# HK32L0xx register map
Vendor: HKMicroChip Ltd.; Series: HK32L0xx; File version: 1.3
CPU: CM0 r0p0, little endian, no MPU, no FPU, 3 interrupt priority bits
Registers are 32-bit, read-write, reset 0x0 unless marked. A register's access mark holds for its fields unless they carry their own. Offsets are from the block's base; [hi:lo] are bit positions; {n}, {i} and the like mark numbered series.

## DAC
Base 0x40007400
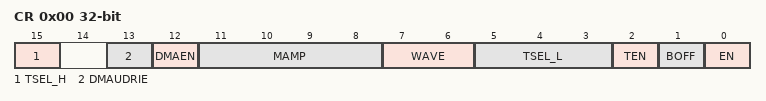
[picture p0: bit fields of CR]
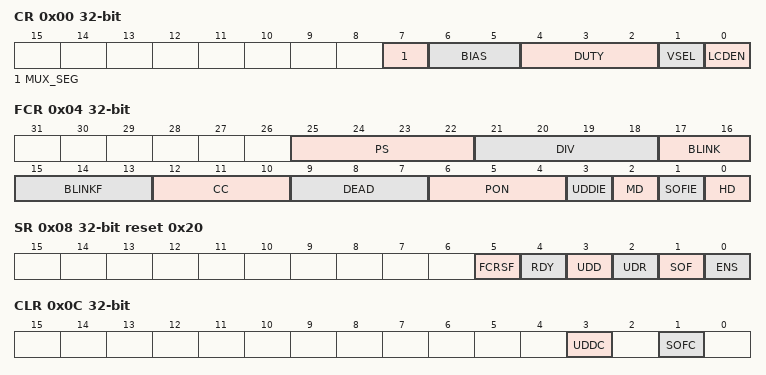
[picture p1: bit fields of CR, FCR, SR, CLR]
0x00 CR
  [15] TSEL_H — DAC trigger channel selection high bit
  [13] DMAUDRIE — DAC channel DMA underrun interrupt enable
  [12] DMAEN — DAC channel DMA enable
  [11:8] MAMP — DAC channel mask/amplitude selector
  [7:6] WAVE — DAC channel noise/triangle wave generation enable
  [5:3] TSEL_L — DAC trigger channel selection low bit
  [2] TEN — DAC channel trigger enable
  [1] BOFF — DAC channel output buffer disable
  [0] EN — DAC channel enable
0x04 SWTRIGR wo
  [0] SWTRIG — DAC channel software trigger
0x08 DHR12R
  [11:0] DACDHR12R — DAC channel 12-bit right-aligned data
0x0C DHR12L
  [15:4] DACDHR12L — DAC channel 12-bit right-aligned data
0x10 DHR8R
  [7:0] DACDHR8R — DAC channel 8-bit right-aligned data
0x2C DOR ro
  [11:0] DACDOR — DAC channel data output
0x34 SR
  [13] DMAUDR — DAC channel DMA underrun flag

## LCD
Base 0x40002400
0x00 CR
  [7] MUX_SEG — Mux segment enable
  [6:5] BIAS — Bias selector
  [4:2] DUTY — Duty selection
  [1] VSEL — Voltage source selection
  [0] LCDEN — LCD controller enable
0x04 FCR
  [25:22] PS — PS 16-bit prescaler
  [21:18] DIV — DIV clock divider
  [17:16] BLINK — Blink mode selection
  [15:13] BLINKF — Blink frequency selection
  [12:10] CC — Contrast control
  [9:7] DEAD — Dead time duration
  [6:4] PON — Pulse ON duration
  [3] UDDIE — Update display done interrupt enable
  [2] MD — Middle drive enable
  [1] SOFIE — Start of frame interrupt enable
  [0] HD — High drive enable
0x08 SR access per field reset 0x20
  [5] FCRSF ro — LCD Frame Control Register Synchronization flag
  [4] RDY ro — Ready flag
  [3] UDD ro — Update Display Done
  [2] UDR rw — Update display request
  [1] SOF ro — Start of frame flag
  [0] ENS ro — LCD enabled status
0x0C CLR wo
  [3] UDDC — Update display done clear
  [1] SOFC — Start of frame flag clear
{0x14+4i} RAM{i} (i=0..15)
  [31:0] SEGMENT_DATA — The Value write to RAM
0x80 COMENR
  [7:0] COMEN — COM Enable
0x84 SEGENR0
  [31:0] SEGEN — SEG Enable

## COMP1
Base 0x40010118
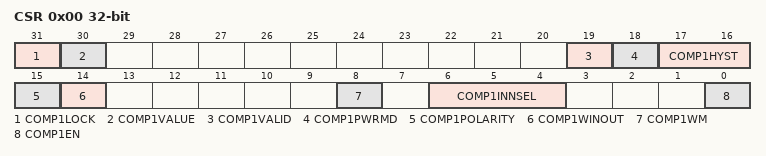
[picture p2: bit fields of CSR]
0x00 CSR access per field
  [31] COMP1LOCK rw — COMP1_CSR register lock bit
  [30] COMP1VALUE ro — Comparator 1 output status bit
  [19] COMP1VALID rw — Comparator 1 valid output selection
  [18] COMP1PWRMD rw — Comparator 1 power mode selection
  [17:16] COMP1HYST rw — Comparator 1 hysteresis
  [15] COMP1POLARITY rw — Comparator 1 polarity selection bit
  [14] COMP1WINOUT rw — Comparator 1 output selection
  [8] COMP1WM rw — Comparator 1 window mode selection bit
  [6:4] COMP1INNSEL rw — Comparator 1 inverting input selection
  [0] COMP1EN rw — Comparator 1 enable bit

## COMP2
Base 0x4001011C
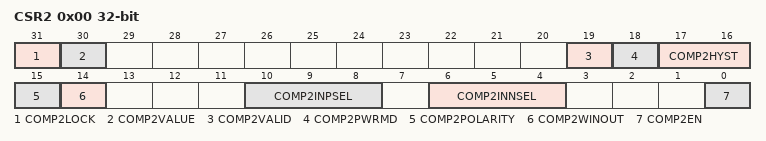
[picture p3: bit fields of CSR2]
0x00 CSR2 access per field
  [31] COMP2LOCK rw — COMP2_CSR register lock bit
  [30] COMP2VALUE ro — Comparator 2 output status bit
  [19] COMP2VALID rw — Comparator 2 valid output selection
  [18] COMP2PWRMD rw — Comparator 2 power mode selection
  [17:16] COMP2HYST rw — Comparator 2 hysteresis
  [15] COMP2POLARITY rw — Comparator 2 polarity selection bit
  [14] COMP2WINOUT rw — Comparator 2 output selection
  [10:8] COMP2INPSEL rw — Comparator 2 non inverting input selection
  [6:4] COMP2INNSEL rw — Comparator 2 inverting input selection
  [0] COMP2EN rw — Comparator 2 enable bit

## OPA1
Base 0x40010238
Same registers: OPA2 0x4001023C, OPA3 0x40010240
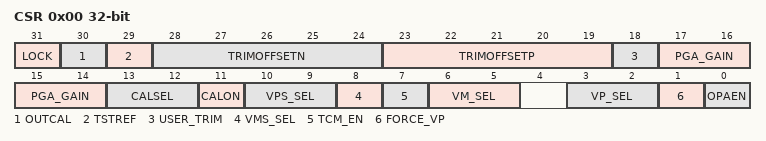
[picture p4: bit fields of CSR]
0x00 CSR access per field
  [31] LOCK rw — OPAx_CSR register lock bit
  [30] OUTCAL ro — OPAx output status flag
  [29] TSTREF rw — OPA1 output to ADC enable
  [28:24] TRIMOFFSETN rw — NMOS
  [23:19] TRIMOFFSETP rw — PMOS
  [18] USER_TRIM rw — User trimming enable
  [17:14] PGA_GAIN rw — Gain in PGA mode configuration
  [13:12] CALSEL rw — Calibration selection
  [11] CALON rw — Calibration mode enable
  [10:9] VPS_SEL rw — OPAx Second Non inverting input selection
  [8] VMS_SEL rw — OPAx Second inverting input selection
  [7] TCM_EN rw — OPAx Default and Second Enable
  [6:5] VM_SEL rw — OPAx inverting input selection
  [3:2] VP_SEL rw — OPAx Non inverting input selection
  [1] FORCE_VP rw — Forces calibration
  [0] OPAEN rw — OPAx enable

## BEEPER
Base 0x40012000
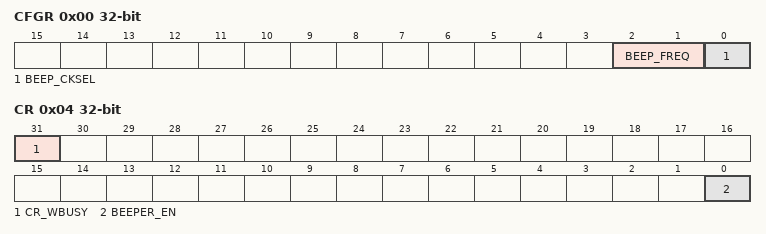
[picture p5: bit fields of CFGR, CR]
0x00 CFGR
  [2:1] BEEP_FREQ — Beep clock source divider
  [0] BEEP_CKSEL — Beep elapsed time clock select
0x04 CR access per field
  [31] CR_WBUSY ro — CR write busy
  [0] BEEPER_EN rw — Beeper enable

## AES
Base 0x40026000
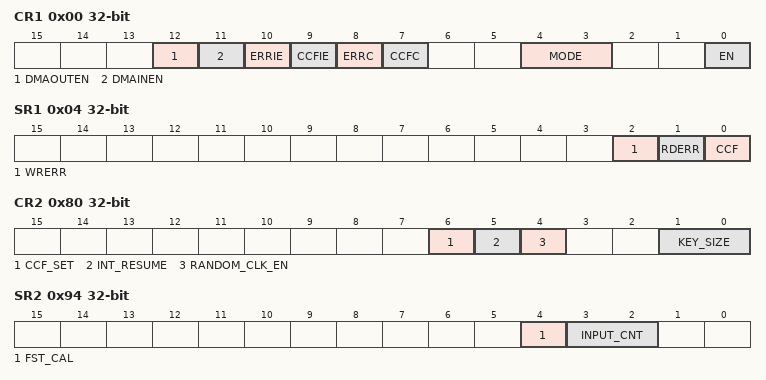
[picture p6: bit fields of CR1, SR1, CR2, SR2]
0x00 CR1
  [12] DMAOUTEN — Enable DMA management of data output phase
  [11] DMAINEN — Enable DMA management of data input phase
  [10] ERRIE — Error interrupt enable
  [9] CCFIE — CCF flag interrupt enable
  [8] ERRC — Error clear
  [7] CCFC — Computation complete flag clear
  [4:3] MODE — AES operating mode selection
  [0] EN — AES enable
0x04 SR1 ro
  [2] WRERR — Write error flag
  [1] RDERR — Read error flag
  [0] CCF — Computation complete flag
0x08 DINR
  [31:0] DINR — Data input register
0x0C DOUTR
  [31:0] DOUTR — Data output register
0x10 KEYR0
  [31:0] KEYR0 — LSB of AES key register
{0x10+4i} KEYR{i} (i=1..3)
  [31:0] KEYR{i} — AES key register
0x80 CR2
  [6] CCF_SET — Force to set bit AES_SR.CCF
  [5] INT_RESUME — Indicate the AES to resume from the interrupt service program
  [4] RANDOM_CLK_EN — Random number of TRNG output to randomize the AES clock
  [1:0] KEY_SIZE
{0x74+4i} KEYR{i} (i=4..6)
  [31:0] KEYR{i} — AES key register
0x90 KEYR7
  [31:0] KEYR7 — MSB of AES key register
0x94 SR2 ro
  [4] FST_CAL — The state of the first operation after the AES_CR1.EN enable
  [3:2] INPUT_CNT — The Number of words already entered into the DINR register

## TRNG
Base 0x40025000
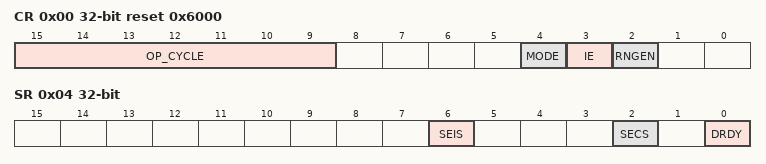
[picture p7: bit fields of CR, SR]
0x00 CR reset 0x6000
  [15:9] OP_CYCLE — Operation cycle
  [4] MODE
  [3] IE — Interrupt enable
  [2] RNGEN — Random number generator enable
0x04 SR access per field
  [6] SEIS rw — Seed error interrupt status
  [2] SECS ro — Seed error current status
  [0] DRDY ro — Data ready
0x08 DR ro
  [31:0] RNDATA — Random data

## DBGMCU
Base 0x40015800
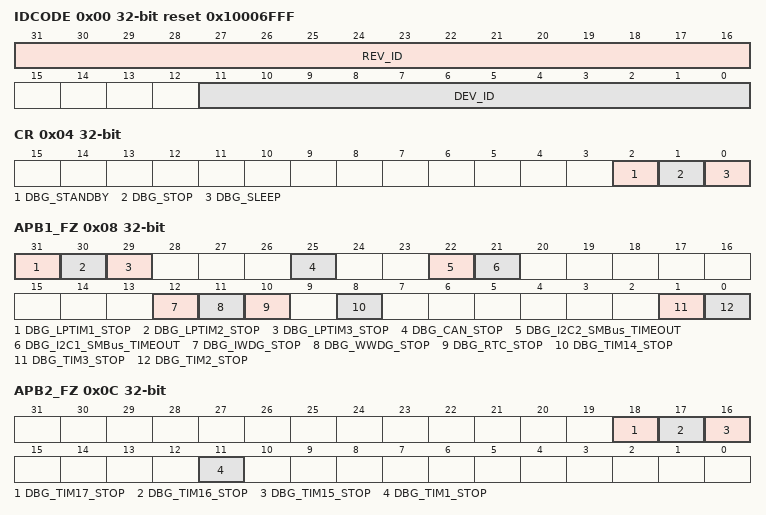
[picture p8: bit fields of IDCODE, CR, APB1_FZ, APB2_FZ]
0x00 IDCODE ro reset 0x10006FFF
  [31:16] REV_ID — Revision identifier
  [11:0] DEV_ID — Device identifier
0x04 CR
  [2] DBG_STANDBY — Debug Standby mode
  [1] DBG_STOP — Debug Stop mode
  [0] DBG_SLEEP — Debug Sleep mode
0x08 APB1_FZ
  [31] DBG_LPTIM1_STOP — LPTIM1 counter stopped when core is halted
  [30] DBG_LPTIM2_STOP — LPTIM2 counter stopped when core is halted
  [29] DBG_LPTIM3_STOP — LPTIM3 counter stopped when core is halted
  [25] DBG_CAN_STOP — Debug CAN stopped when core is halted
  [22] DBG_I2C2_SMBus_TIMEOUT — I2C2 SMBUS timeout mode stopped when core is halted
  [21] DBG_I2C1_SMBus_TIMEOUT — I2C1 SMBUS timeout mode stopped when core is halted
  [12] DBG_IWDG_STOP — Debug independent watchdog stopped when core is halted
  [11] DBG_WWDG_STOP — Debug window watchdog stopped when core is halted
  [10] DBG_RTC_STOP — Debug RTC stopped when core is halted
  [8] DBG_TIM14_STOP — Debug TIM14 stopped when core is halted
  [1] DBG_TIM3_STOP — Debug TIM3 stopped when core is halted
  [0] DBG_TIM2_STOP — Debug TIM2 stopped when core is halted
0x0C APB2_FZ
  [18] DBG_TIM17_STOP — Debug TIM17 stopped when core is halted
  [17] DBG_TIM16_STOP — Debug TIM16 stopped when core is halted
  [16] DBG_TIM15_STOP — Debug TIM15 stopped when core is halted
  [11] DBG_TIM1_STOP — Debug TIM1 stopped when core is halted
